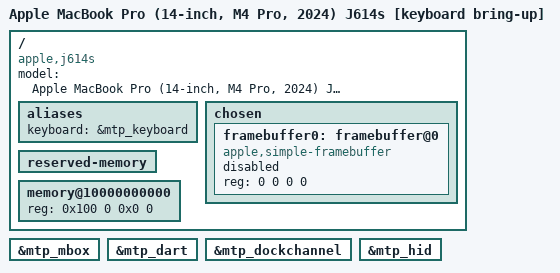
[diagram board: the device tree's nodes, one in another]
// SPDX-License-Identifier: GPL-2.0+ OR MIT
/*
 * Apple MacBook Pro (14-inch, M4 Pro, 2024) J614s keyboard bring-up.
 *
 * Enables the measured mailbox-based MTP path for the internal keyboard.
 * Trackpad firmware/power sequencing is deliberately left out of this
 * clean-room variant.
 */

/dts-v1/;

#include "t6040.dtsi"

/ {
	compatible = "apple,j614s", "apple,t6040", "apple,arm-platform";
	model = "Apple MacBook Pro (14-inch, M4 Pro, 2024) J614s [keyboard bring-up]";

	aliases {
		keyboard = &mtp_keyboard;
	};

	chosen {
		#address-cells = <2>;
		#size-cells = <2>;
		ranges;

		framebuffer0: framebuffer@0 {
			compatible = "apple,simple-framebuffer", "simple-framebuffer";
			reg = <0 0 0 0>;
			status = "disabled";
		};
	};

	reserved-memory {
		#address-cells = <2>;
		#size-cells = <2>;
		ranges;
	};

	memory@10000000000 {
		device_type = "memory";
		reg = <0x100 0 0x0 0>;
	};
};

&mtp_mbox {
	status = "okay";
};

&mtp_dart {
	status = "okay";
};

&mtp_dockchannel {
	status = "okay";
};

&mtp_hid {
	status = "okay";
};
